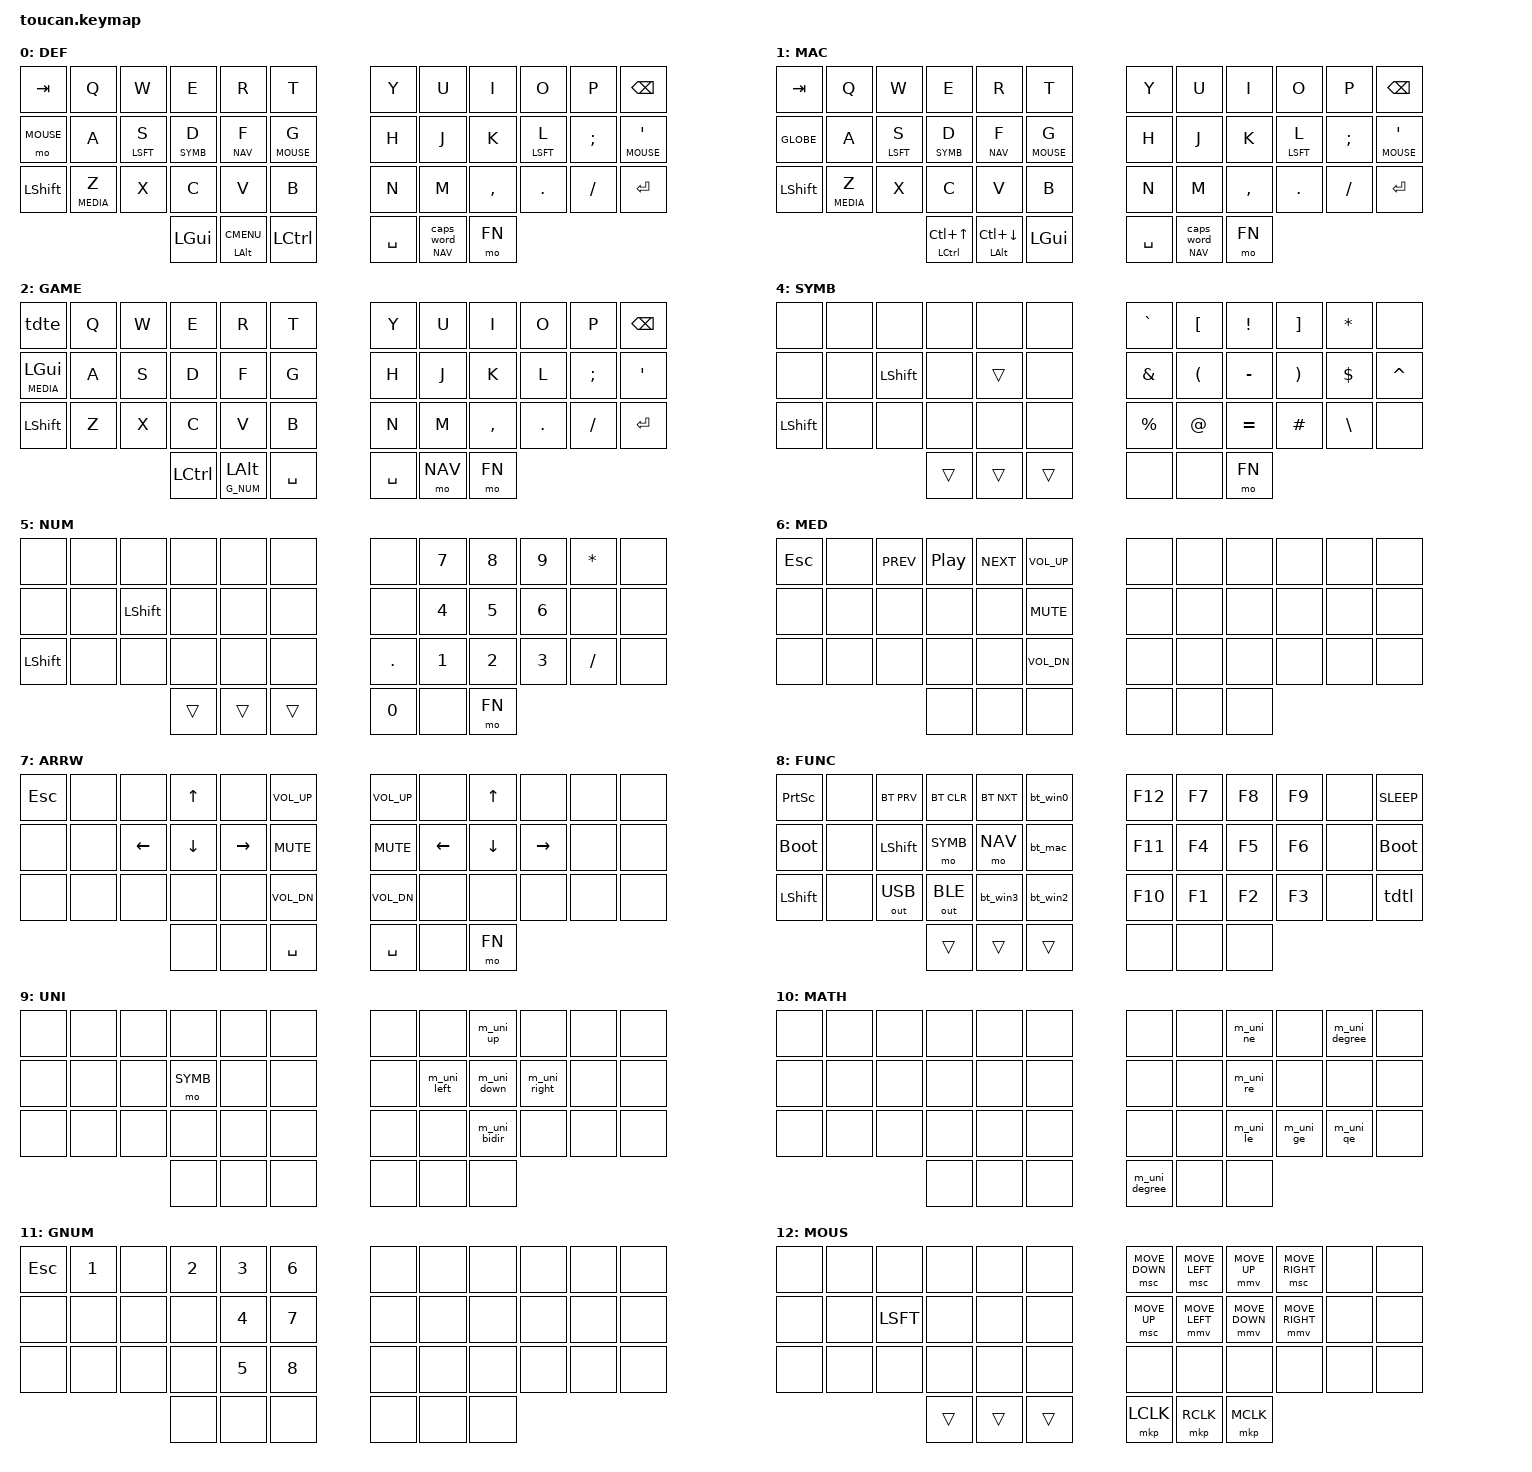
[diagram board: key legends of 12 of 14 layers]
#include <behaviors.dtsi>
#include <dt-bindings/zmk/keys.h>
#include <dt-bindings/zmk/mouse.h>
#include <dt-bindings/zmk/bt.h>
#include <dt-bindings/zmk/outputs.h>
#include <dt-bindings/zmk/input_transform.h>

#define DEFAULT 0
#define DEFAULT_MAC 1
#define GAME 2
#define NAV 3
#define SYMB 4
#define NUM 5
#define MEDIA 6
#define ARROWS 7
#define FN 8
#define UNI_NAV 9 // navigation-like unicode characters (e.g., arrows)
#define UNI_MATH 10 // math related unicode characters (e.g., approximately equals)
#define G_NUM 11   // Numbers (1-5) accessible from the GAME layer
#define MOUSE 12
#define SCROLL_Y_INVERT 13

&caps_word {
    continue-list = <UNDERSCORE MINUS FSLH BSLH N0 N1 N2 N3 N4 N5 N6 N7 N8 N9>;
    timeout = <3>;
    break-on-mod; /* stop caps_word when pressing a modifier */
};

#if defined(HAS_TRACKPAD)
&pointer_accel {
    input-type = <INPUT_EV_REL>;
    min-factor = <900>;        // 0.9x minimum
    max-factor = <3000>;       // 4.0x maximum
    speed-threshold = <500>;  // Start accelerating earlier
    speed-max = <6000>;          // 6000 counts/sec for max accel
    acceleration-exponent = <2>; // Cubic acceleration curve
    track-remainders;          // Track fractional movements
};

&trackpad_listener {
    /delete-node/ scroller;

    input-processors = <
        &zip_xy_scaler 100 100
        &zip_scroll_scaler 1 50
        &zip_zoom_mapper
        &is_touching_processor
        &swipe_button_mapper
        &pointer_accel
    >;

    // `scroller_y_invert` must come before `scroller`. Explanation:
    //   * On non-Mac BT profiles (e.g., 0): Layer NAV enables `scroller`
    //   * On Mac BT profiles (e.g., 1): Layers DEFAULT_MAC + NAV enabled `scroller_y_invert`
    // Beucase layer NAV is shared between both cases, if `scroller` were to be first,
    // it would always be matched. This order forces trying to match DEFAULT_MAC + NAV before
    // trying to match just NAV. 
    // Disabled for now.
    /*
    * scroller_y_invert {
    *   layers = <SCROLL_Y_INVERT>;
    *   input-processors = <
    *       &zip_xy_to_scroll_mapper
    *       &zip_scroll_scaler 1 20
    *       &zip_scroll_transform INPUT_TRANSFORM_Y_INVERT
    *   >;
    * };
    * 
    * scroller {
    *     layers = <NAV>;
    *     input-processors = <
    *         &zip_xy_to_scroll_mapper
    *         &zip_scroll_scaler 1 20
    *         &zip_scroll_transform INPUT_TRANSFORM_X_INVERT
    *     >;
    * };
    */
};
#endif

/ {
    conditional_layers {
        compatible = "zmk,conditional-layers";
        tri_layer_numbers {
                if-layers = <NAV SYMB>;
                then-layer = <NUM>;
        };
        tri_layer_unicode_nav {
                if-layers = <NAV FN>;
                then-layer = <UNI_NAV>;
        };
        tri_layer_unicode_math {
                if-layers = <NAV SYMB FN>;
                then-layer = <UNI_MATH>;
        };
        tri_layer_nav_y_invert {
                if-layers = <DEFAULT_MAC NAV>;
                then-layer = <SCROLL_Y_INVERT>;
        };
    };

    behaviors {
        mltp: media_layer_tap_preferred {
            compatible = "zmk,behavior-hold-tap";
            #binding-cells = <2>;
            flavor = "tap-preferred";
            tapping-term-ms = <300>;
            // quick-tap-ms enables repeated CTRL-Z by holding CTRL and double
            // tapping and holding Z.
            quick-tap-ms = <200>;
            bindings = <&mo>, <&kp>;
        };

        tdte: tap_dance_tab_esc {
            compatible = "zmk,behavior-tap-dance";
            #binding-cells = <0>;
            tapping-term-ms = <200>;
            bindings = <&kp TAB>, <&kp ESC>;
        };

        tdtl: tap_dance_to_layer {
            compatible = "zmk,behavior-tap-dance";
            #binding-cells = <0>;
            tapping-term-ms = <1000>;
            bindings = <&to DEFAULT>, <&to GAME>, <&to ARROWS>;
        };

        ht_mac: hold_tap_mac {
            compatible = "zmk,behavior-hold-tap";
            #binding-cells = <2>;
            tapping-term-ms = <150>;
            flavor = "tap-preferred";
            bindings = <&kp>, <&kp>;
        };

        // From docs (https://zmk.dev/docs/behaviors/hold-tap#example-use-cases)
        lh_pht: left_hand_positional_hold_tap {
            compatible = "zmk,behavior-hold-tap";
            #binding-cells = <2>;
            flavor = "tap-preferred";
            tapping-term-ms = <150>;                        // <---[[produces tap if held longer than tapping-term-ms]]
            // Retro tap fixes this issue:
            // 1. Press one home row mod
            // 2. Press a second home row mod
            // 3. Wait a bit (slow typing)
            // 4. Release second home row mod
            // Expected: First home row mod hold behavior applied to second home row mod tap behavior
            // Actual: Nothing happens, because the second home row mod is held
            //     long enough for hold behavior to be invoked, but no other key
            //     (except for the first home row mod which was already pressed)
            //     gets tapped. Retro tap foces the second home row mod to emit
            //     tap behavior when it finally gets released.
            retro-tap;
            bindings = <&kp>, <&kp>;
            hold-trigger-key-positions = <
                6  7  8  9  10    // Y - P
                18 19 20 21 22 23 // H - '
                30 31 32 33 34 35 // N - Enter
            >;    // <---[[right-hand keys]]
            // quick-tap-ms enables tap-then-hold continuous key repeat for WASD navigation
            quick-tap-ms = <200>;
        };

        // From docs (https://zmk.dev/docs/behaviors/hold-tap#example-use-cases)
        rh_pht: right_hand_positional_hold_tap {
            compatible = "zmk,behavior-hold-tap";
            #binding-cells = <2>;
            flavor = "tap-preferred";
            tapping-term-ms = <150>;                        // <---[[produces tap if held longer than tapping-term-ms]]
            // See retro-tap expalanation above
            retro-tap;
            bindings = <&kp>, <&kp>;
            hold-trigger-key-positions = <
                0  1  2  3  4  5  // Tab - T
                13 14 15 16 17    // A   - G
                25 26 27 28 29    // Z   - B
            >;    // <---[[left hand keys]]
        };

        // Usage example: &lt_cw NAV 0
        lt_cw: layer_tap_caps_word {
            compatible = "zmk,behavior-hold-tap";
            #binding-cells = <2>;
            tapping-term-ms = <200>;
            flavor = "tap-preferred";
            bindings = <&mo>, <&caps_word>;
        };

        lt_mk: layer_tap_mo_kp {
            compatible = "zmk,behavior-hold-tap";
            #binding-cells = <2>;
            tapping-term-ms = <150>;
            flavor = "tap-preferred";
            quick-tap-ms = <200>;
            bindings = <&mo>, <&kp>;
        };
    };

    macros {
        bt_mac: bt_mac {
            compatible = "zmk,behavior-macro";
            #binding-cells = <0>;
            wait-ms = <0>;
            tap-ms = <0>;
            bindings = <&bt BT_SEL 1 &to DEFAULT_MAC>;
        };

        bt_win0: bt_win0 {
            compatible = "zmk,behavior-macro";
            #binding-cells = <0>;
            wait-ms = <0>;
            tap-ms = <0>;
            bindings = <&bt BT_SEL 0 &to DEFAULT>;
        };

        bt_win2: bt_win2 {
            compatible = "zmk,behavior-macro";
            #binding-cells = <0>;
            wait-ms = <0>;
            tap-ms = <0>;
            bindings = <&bt BT_SEL 2 &to DEFAULT>;
        };

        bt_win3: bt_win3 {
            compatible = "zmk,behavior-macro";
            #binding-cells = <0>;
            wait-ms = <0>;
            tap-ms = <0>;
            bindings = <&bt BT_SEL 3 &to DEFAULT>;
        };
        m_uni_le: mac_unicode_less_than_or_equal {
            compatible = "zmk,behavior-macro";
            #binding-cells = <0>;
            wait-ms = <10>;
            tap-ms = <10>;
            bindings = <&macro_press &kp LALT>, <&macro_tap &kp N2 &kp N2 &kp N6 &kp N4>, <&macro_release &kp LALT>;
        };

        m_uni_ge: mac_unicode_greater_than_or_equal {
            compatible = "zmk,behavior-macro";
            #binding-cells = <0>;
            wait-ms = <10>;
            tap-ms = <10>;
            bindings = <&macro_press &kp LALT>, <&macro_tap &kp N2 &kp N2 &kp N6 &kp N5>, <&macro_release &kp LALT>;
        };

        m_uni_qe: mac_unicode_questioned_equals {
            compatible = "zmk,behavior-macro";
            #binding-cells = <0>;
            wait-ms = <10>;
            tap-ms = <10>;
            bindings = <&macro_press &kp LALT>, <&macro_tap &kp N2 &kp N2 &kp N5 &kp F>, <&macro_release &kp LALT>;
        };

        m_uni_re: mac_unicode_roughly_equals {
            compatible = "zmk,behavior-macro";
            #binding-cells = <0>;
            wait-ms = <10>;
            tap-ms = <10>;
            bindings = <&macro_press &kp LALT>, <&macro_tap &kp N2 &kp N2 &kp N4 &kp N8>, <&macro_release &kp LALT>;
        };

        m_uni_ne: mac_unicode_not_equals {
            compatible = "zmk,behavior-macro";
            #binding-cells = <0>;
            wait-ms = <10>;
            tap-ms = <10>;
            bindings = <&macro_press &kp LALT>, <&macro_tap &kp N2 &kp N2 &kp N6 &kp N0>, <&macro_release &kp LALT>;
        };

        m_uni_degree: mac_unicode_degree {
            compatible = "zmk,behavior-macro";
            #binding-cells = <0>;
            wait-ms = <10>;
            tap-ms = <10>;
            bindings = <&macro_press &kp LALT>, <&macro_tap &kp N0 &kp N0 &kp B &kp N0>, <&macro_release &kp LALT>;
        };

        m_uni_left: mac_unicode_left {
            compatible = "zmk,behavior-macro";
            #binding-cells = <0>;
            wait-ms = <10>;
            tap-ms = <10>;
            bindings = <&macro_press &kp LALT>, <&macro_tap &kp N2 &kp N1 &kp N9 &kp N0>, <&macro_release &kp LALT>;
        };

        m_uni_up: mac_unicode_up {
            compatible = "zmk,behavior-macro";
            #binding-cells = <0>;
            wait-ms = <10>;
            tap-ms = <10>;
            bindings = <&macro_press &kp LALT>, <&macro_tap &kp N2 &kp N1 &kp N9 &kp N1>, <&macro_release &kp LALT>;
        };

        m_uni_right: mac_unicode_right {
            compatible = "zmk,behavior-macro";
            #binding-cells = <0>;
            wait-ms = <10>;
            tap-ms = <10>;
            bindings = <&macro_press &kp LALT>, <&macro_tap &kp N2 &kp N1 &kp N9 &kp N2>, <&macro_release &kp LALT>;
        };

        m_uni_down: mac_unicode_down {
            compatible = "zmk,behavior-macro";
            #binding-cells = <0>;
            wait-ms = <10>;
            tap-ms = <10>;
            bindings = <&macro_press &kp LALT>, <&macro_tap &kp N2 &kp N1 &kp N9 &kp N3>, <&macro_release &kp LALT>;
        };

        m_uni_bidir: mac_unicode_bidirectional {
            compatible = "zmk,behavior-macro";
            #binding-cells = <0>;
            wait-ms = <10>;
            tap-ms = <10>;
            bindings = <&macro_press &kp LALT>, <&macro_tap &kp N2 &kp N1 &kp N9 &kp N4>, <&macro_release &kp LALT>;
        };
    };

    keymap {
        compatible = "zmk,keymap";

        default_layer {
            display-name = "DEF";
            bindings = <
&kp TAB    &kp Q         &kp W          &kp E         &kp R            &kp T        /*|*/ &kp Y     &kp U        &kp I     &kp O          &kp P    &kp BSPC
&mo MOUSE  &kp A         &lh_pht LSFT S &lt_mk SYMB D &lt NAV F        &lt MOUSE G  /*|*/ &kp H     &kp J        &kp K     &rh_pht LSFT L &kp SEMI &lt MOUSE SQT
&kp LSHFT  &mltp MEDIA Z &kp X          &kp C         &kp V            &kp B        /*|*/ &kp N     &kp M        &kp COMMA &kp DOT        &kp FSLH &kp RET
                                        &kp LGUI      &mt LALT K_CMENU &kp LCTRL    /*|*/ &kp SPACE &lt_cw NAV 0 &mo FN
            >;
        };

        default_mac_layer {
            display-name = "MAC";
            bindings = <
&kp TAB   &kp Q         &kp W          &kp E         &kp R            &kp T        /*|*/ &kp Y     &kp U        &kp I     &kp O          &kp P    &kp BSPC
&kp GLOBE &kp A         &lh_pht LSFT S &lt_mk SYMB D &lt NAV F        &lt MOUSE G  /*|*/ &kp H     &kp J        &kp K     &rh_pht LSFT L &kp SEMI &lt MOUSE SQT
&kp LSHFT &mltp MEDIA Z &kp X          &kp C         &kp V            &kp B        /*|*/ &kp N     &kp M        &kp COMMA &kp DOT        &kp FSLH &kp RET
                                       &ht_mac LCTRL LC(UP) &ht_mac LALT LC(DOWN) &kp LGUI     /*|*/ &kp SPACE &lt_cw NAV 0 &mo FN
            >;
        };

        gaming_layer {
            display-name = "GAME";
            bindings = <
&tdte          &kp Q &kp W &kp E     &kp R             &kp T     /*|*/ &kp Y     &kp U   &kp I     &kp O   &kp P    &kp BSPC
&lt MEDIA LGUI &kp A &kp S &kp D     &kp F             &kp G     /*|*/ &kp H     &kp J   &kp K     &kp L   &kp SEMI &kp SQT
&kp LSHFT      &kp Z &kp X &kp C     &kp V             &kp B     /*|*/ &kp N     &kp M   &kp COMMA &kp DOT &kp FSLH &kp RET
                           &kp LCTRL &lt_mk G_NUM LALT &kp SPACE /*|*/ &kp SPACE &mo NAV &mo FN
            >;
        };

        navigation_layer {
            display-name = "NAV";
            bindings = <
&none     &kp ESC &none    &none    &none    &kp LC(LA(LS(T))) /*|*/ &kp PG_UP &kp HOME &kp UP           &kp END           &kp DEL &kp BSPC
&trans    &none   &kp LSFT &trans   &none    &none             /*|*/ &kp PG_DN &kp LEFT &kp DOWN         &kp RIGHT         &none   &none
&kp LSHFT &none   &none    &none    &none    &none             /*|*/ &none     &none    &kp LC(LS(LEFT)) &kp LC(LS(RIGHT)) &none   &none
                           &trans   &trans   &trans            /*|*/ &kp BSPC  &none    &mo FN
            >;
        };

        symbols_layer {
            display-name = "SYMB";
            bindings = <
&none     &none &none     &none    &none    &none       /*|*/ &kp GRAVE &kp LBKT &kp EXCL  &kp RBKT &kp STAR &none
&none     &none &kp LSHFT &none    &trans   &none       /*|*/ &kp AMPS  &kp LPAR &kp MINUS &kp RPAR &kp DLLR &kp CARET
&kp LSHFT &none &none     &none    &none    &none       /*|*/ &kp PRCNT &kp AT   &kp EQUAL &kp HASH &kp BSLH &none
                          &trans   &trans   &trans      /*|*/ &none     &none    &mo FN
            >;
        };

        numbers_layer {
            display-name = "NUM";
            bindings = <
&none     &none &none     &none    &none    &none     /*|*/ &none   &kp N7 &kp N8 &kp N9 &kp STAR &none
&none     &none &kp LSHFT &none    &none    &none     /*|*/ &none   &kp N4 &kp N5 &kp N6 &none    &none
&kp LSHFT &none &none     &none    &none    &none     /*|*/ &kp DOT &kp N1 &kp N2 &kp N3 &kp FSLH &none
                          &trans   &trans   &trans    /*|*/ &kp N0  &none  &mo FN
            >;
        };

        media_layer {
            display-name = "MED";
            bindings = <
&kp ESC &none &kp C_PREV &kp C_PP &kp C_NEXT &kp C_VOL_UP /*|*/ &none &none &none &none &none &none
&none   &none &none      &none    &none      &kp C_MUTE   /*|*/ &none &none &none &none &none &none
&none   &none &none      &none    &none      &kp C_VOL_DN /*|*/ &none &none &none &none &none &none
                         &none    &none      &none        /*|*/ &none &none &none
            >;
        };

        arrows_layer {
            display-name = "ARRW";
            bindings = <
&kp ESC &none &none    &kp UP   &none     &kp C_VOL_UP /*|*/ &kp C_VOL_UP &none    &kp UP   &none     &none &none
&none   &none &kp LEFT &kp DOWN &kp RIGHT &kp C_MUTE   /*|*/ &kp C_MUTE   &kp LEFT &kp DOWN &kp RIGHT &none &none
&none   &none &none    &none    &none     &kp C_VOL_DN /*|*/ &kp C_VOL_DN &none    &none    &none     &none &none
                       &none    &none     &kp SPACE    /*|*/ &kp SPACE    &none    &mo FN
            >;
        };

        function_layer {
            display-name = "FUNC";
            bindings = <
&kp PSCRN   &none &bt BT_PRV   &bt BT_CLR   &bt BT_NXT        &bt_win0 /*BT0*/ /*|*/ &kp F12 &kp F7 &kp F8 &kp F9 &none &kp C_SLEEP
&bootloader &none &kp LSHFT    &mo SYMB     &mo NAV           &bt_mac  /*BT1*/ /*|*/ &kp F11 &kp F4 &kp F5 &kp F6 &none &bootloader
&kp LSHFT   &none &out OUT_USB &out OUT_BLE &bt_win3  /*BT3*/ &bt_win2 /*BT2*/ /*|*/ &kp F10 &kp F1 &kp F2 &kp F3 &none &tdtl
                               &trans       &trans            &trans           /*|*/ &none   &none  &none
            >;
        };

        unicode_nav_layer {
            display-name = "UNI";
            bindings = <
&none &none &none &none    &none &none /*|*/ &none &none       &m_uni_up    &none        &none &none
&none &none &none &mo SYMB &none &none /*|*/ &none &m_uni_left &m_uni_down  &m_uni_right &none &none
&none &none &none &none    &none &none /*|*/ &none &none       &m_uni_bidir &none        &none &none
                  &none    &none &none /*|*/ &none &none       &none
            >;
        };

        unicode_math_layer {
            display-name = "MATH";
            bindings = <
&none &none &none &none &none &none /*|*/ &none &none   &m_uni_ne &none     &m_uni_degree &none
&none &none &none &none &none &none /*|*/ &none &none   &m_uni_re &none     &none         &none
&none &none &none &none &none &none /*|*/ &none &none   &m_uni_le &m_uni_ge &m_uni_qe     &none
                  &none &none &none /*|*/ &m_uni_degree &none &none
            >;
        };

        game_number_layer {
            display-name = "GNUM";
            bindings = <
&kp ESC &kp N1 &none &kp N2 &kp N3 &kp N6 /*|*/ &none &none &none &none &none &none
&none   &none  &none &none  &kp N4 &kp N7 /*|*/ &none &none &none &none &none &none
&none   &none  &none &none  &kp N5 &kp N8 /*|*/ &none &none &none &none &none &none
                     &none  &none  &none  /*|*/ &none &none &none
            >;
        };

        mouse_layer {
            display-name = "MOUS";
            bindings = <
&none &none &none    &none   &none     &none     /*|*/ &msc MOVE_DOWN &msc MOVE_LEFT &mmv MOVE_UP   &msc MOVE_RIGHT &none &none
&none &none &kp LSFT &none   &none     &none     /*|*/ &msc MOVE_UP   &mmv MOVE_LEFT &mmv MOVE_DOWN &mmv MOVE_RIGHT &none &none
&none &none &none    &none   &none     &none     /*|*/ &none          &none          &none          &none           &none &none
                     &trans   &trans   &trans    /*|*/ &mkp LCLK      &mkp RCLK      &mkp MCLK
            >;
        };

        scroll_y_invert_layer {
            display-name = "SCRINV";
            bindings = <
&trans &trans &trans &trans &trans &trans    &trans &trans &trans &trans &trans &trans
&trans &trans &trans &trans &trans &trans    &trans &trans &trans &trans &trans &trans
&trans &trans &trans &trans &trans &trans    &trans &trans &trans &trans &trans &trans
                     &trans &trans &trans    &trans &trans &trans
            >;
        };
    }; // keymap
};
